AUTOSAR XML (schema 00052)
package /Components
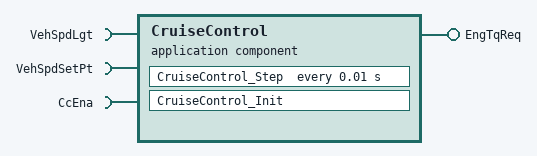
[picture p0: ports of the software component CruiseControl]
  application sw component type CruiseControl
    require port VehSpdLgt: required-interface=VehSpdLgt
    require port VehSpdSetPt: required-interface=VehSpdSetPt
    require port CcEna: required-interface=CcEna
    provide port EngTqReq: provided-interface=EngTqReq
    behavior IB
      timing event CruiseControl_Step_Ev: start-on-event=CruiseControl_Step, period=0.01
      runnable CruiseControl_Step
      runnable CruiseControl_Init
